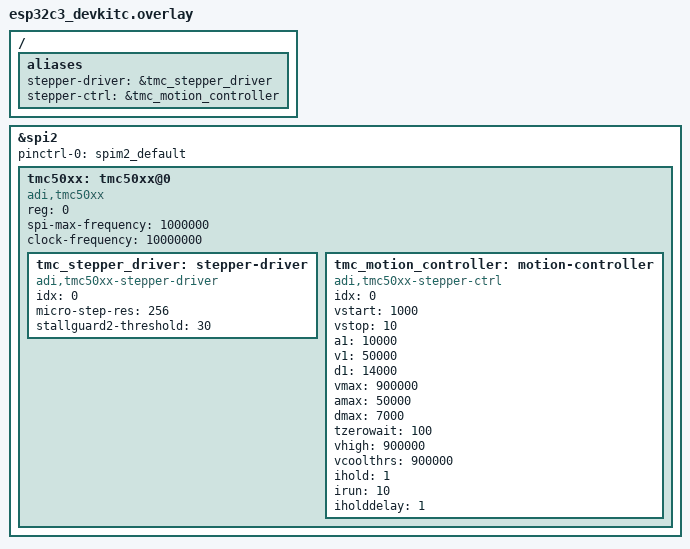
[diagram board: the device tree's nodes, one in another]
/*
 * Copyright (c) 2026
 * SPDX-License-Identifier: Apache-2.0
 *
 * samples/drivers/stepper/tmc50xx: TMC50xx on the ESP32-C3's GP-SPI2, CS0,
 * answered by the browser through hw/ssi/host_spi.c. Aliases stepper-driver
 * and stepper-ctrl match the stock sample.
 *
 * Self-contained, like its Cortex-A53 twin: it turns the bus on itself rather
 * than composing with esp32-spi, which would put a JEDEC NOR on the same chip
 * select.
 */

&spi2 {
	status = "okay";
	#address-cells = <1>;
	#size-cells = <0>;
	pinctrl-0 = <&spim2_default>;
	pinctrl-names = "default";

	tmc50xx: tmc50xx@0 {
		compatible = "adi,tmc50xx";
		reg = <0>;
		spi-max-frequency = <1000000>;
		clock-frequency = <10000000>;
		status = "okay";

		tmc_stepper_driver: stepper-driver {
			compatible = "adi,tmc50xx-stepper-driver";
			idx = <0>;
			micro-step-res = <256>;
			stallguard2-threshold = <30>;
		};

		tmc_motion_controller: motion-controller {
			compatible = "adi,tmc50xx-stepper-ctrl";
			idx = <0>;
			vstart = <1000>;
			vstop = <10>;
			a1 = <10000>;
			v1 = <50000>;
			d1 = <14000>;
			vmax = <900000>;
			amax = <50000>;
			dmax = <7000>;
			tzerowait = <100>;
			vhigh = <900000>;
			vcoolthrs = <900000>;
			ihold = <1>;
			irun = <10>;
			iholddelay = <1>;
		};
	};
};

/ {
	aliases {
		stepper-driver = &tmc_stepper_driver;
		stepper-ctrl = &tmc_motion_controller;
	};
};
